# nrf7140_bbpr register map
Vendor: Nordic Semiconductor; Series: nRF71; File version: 1
Registers are 32-bit, read-write, reset 0x0 unless marked. A register's access mark holds for its fields unless they carry their own. Offsets are from the block's base; [hi:lo] are bit positions; lines under a group give offsets from that group; {n}, {i} and the like mark numbered series; 'fields as' and 'values as' point back to an identical list.

## GLOBAL_PCGCSBUS — PCGCSlave
Base 0x4900CF00; alternate view of GLOBAL_GFXPLLPM
{0xC00+4i} PENALTY[{i}] (i=0..1) reset 0xFFFFFFFC — Description collection: Penalty level for power/clock pair n. When FULL_PCP_ZERO feature is not supported, PENALTY[0] address overlaps the PENALTY0 address and register description for PENALTY[0] is not valid.
  [1:0] PENALTY — Penalty level
0xC00 PENALTY0 (alternate view of PENALTY[*]) — Penalty level for power/clock pair 0. The register description is valid only when FULL_PCP_ZERO feature is not supported
  [1:0] PENALTY ro — Penalty level
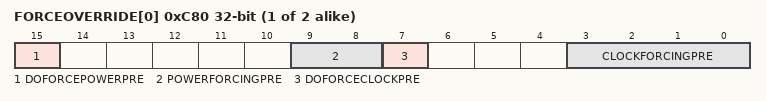
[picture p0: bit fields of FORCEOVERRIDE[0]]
{0xC80+4i} FORCEOVERRIDE[{i}] (i=0..1) — Description collection: Force override of power/clock pair n.
  [15] DOFORCEPOWERPRE, [9:8] POWERFORCINGPRE, [7] DOFORCECLOCKPRE, [3:0] CLOCKFORCINGPRE

## GLOBAL_LRCCONF300 — LRCCONF 0
Base 0x4900E000
Same registers: GLOBAL_LRCCONF310 0x4901E000, GLOBAL_LRCCONF_SDCARD 0x4F8CA000
{0x0+4i} TASKS_REQCLKSRC[{i}] (i=0..7) wo — Description collection: Request the clock source for clock [n]
  [0] TASKS_REQCLKSRC — Request the clock source for clock [n]
    1=Trigger task
{0x20+4i} TASKS_STOPREQCLKSRC[{i}] (i=0..7) wo — Description collection: Stop requesting the clock source for clock [n]
  [0] TASKS_STOPREQCLKSRC — Stop requesting the clock source for clock [n]
    1=Trigger task
0x40 TASKS_CONSTLAT group — Peripheral tasks.
  0x00 ENABLE wo — Enable constant latency mode
    [0] ENABLE
      1=Trigger task
  0x04 DISABLE wo — Disable constant latency mode
    [0] DISABLE
      1=Trigger task
0x48 TASKS_SYSTEMOFF group — Peripheral tasks.
  0x00 NOTREADY wo — Not ready to go to System OFF
    [0] NOTREADY
      1=Trigger task
  0x04 READY wo — Ready to go to System OFF
    [0] READY
      1=Trigger task
0x50 TASKS_REQHFXO wo — Request HFXO
  [0] TASKS_REQHFXO
    1=Trigger task
0x54 TASKS_STOPREQHFXO wo — Stop requesting HFXO
  [0] TASKS_STOPREQHFXO
    1=Trigger task
{0x100+4i} EVENTS_CLKSRCSTARTED[{i}] (i=0..7) — Description collection: Clock source is started for clock [n]
  [0] EVENTS_CLKSRCSTARTED — Clock source is started for clock [n]
    0=NotGenerated (Event not generated); 1=Generated (Event generated)
0x120 EVENTS_HFXOSTARTED — HFXO is started
  [0] EVENTS_HFXOSTARTED
    values as EVENTS_CLKSRCSTARTED[0].EVENTS_CLKSRCSTARTED
{0x400+8i} CLKSTAT[{i}] (i=0..7) group — Unspecified
  0x00 RUN — Description cluster: Status indicating that TASKS_REQCLKSRC task has been triggered for clock [n].
    [0] STATUS ro — Clock start task triggered or not
      0=NotTriggered (Task not triggered); 1=Triggered (Task triggered)
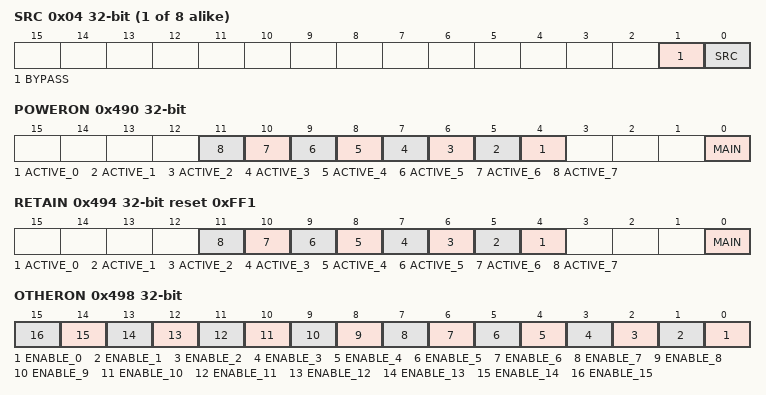
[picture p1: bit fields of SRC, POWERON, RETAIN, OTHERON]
  0x04 SRC — Description cluster: Status indicating clock source for clock [n]
    [1] BYPASS ro — Clock source bypass status
      0=Disable (Clock source bypass is disabled.); 1=Enable (Clock source bypass is enabled.)
    [0] SRC ro — Clock source status
      0=OpenLoop; 1=ClosedLoop
{0x440+8i} CLKCTRL[{i}] (i=0..7) group — Unspecified
  0x00 ALWAYSRUN — Description cluster: Force the clock [n] and tree running always
    [0] FORCE — Force the clock always running
      0=Automatic clock control enabled; 1=AlwaysRun (Clock always running)
  0x04 SRC — Description cluster: Select the clock source for clock [n]
    [1] BYPASS — Clock source bypass
      0=Disable the clock source bypass; 1=Enable the clock source bypass
    [0] SRC — Clock source
      0=OpenLoop; 1=ClosedLoop
0x480 CONSTLATSTAT ro — Status of constant latency
  [0] STATUS
    0=Disable (Constant latency disabled.); 1=Enable (Constant latency enabled.)
0x490 POWERON — Force power domain ON
  [all] fields
    0=Automatic power control enabled; 1=AlwaysOn (Keep the power domain ON even though there is no request)
  [n+4] ACTIVE_{n} (n=0..7) — Force the active power domain[{n}] ON
  [0] MAIN — Force the main power domain ON
0x494 RETAIN reset 0xFF1 — Retain power domain
  [all] fields
    0=Disable (Retain disabled); 1=Enable (Retain enabled)
  [n+4] ACTIVE_{n} (n=0..7) — Retain the active power domain[{n}]
  [0] MAIN ro — Retain the main power domain
0x498 OTHERON — Request other domain ON
  [all] fields
    0=Automatic power control enabled; 1=AlwaysOn (Request to keep the other power domain ON even though there is no request)
  [n] ENABLE_{n} (n=0..15) — Request power domain[{n}] ON
{0x500+4i} AX2XWAITSTATES[{i}] (i=0..15) — Description collection: AX2X bridge waitstates for the domain [n], where n is the Domain ID.
  [2:0] WAITSTATES — Number of waitstates
